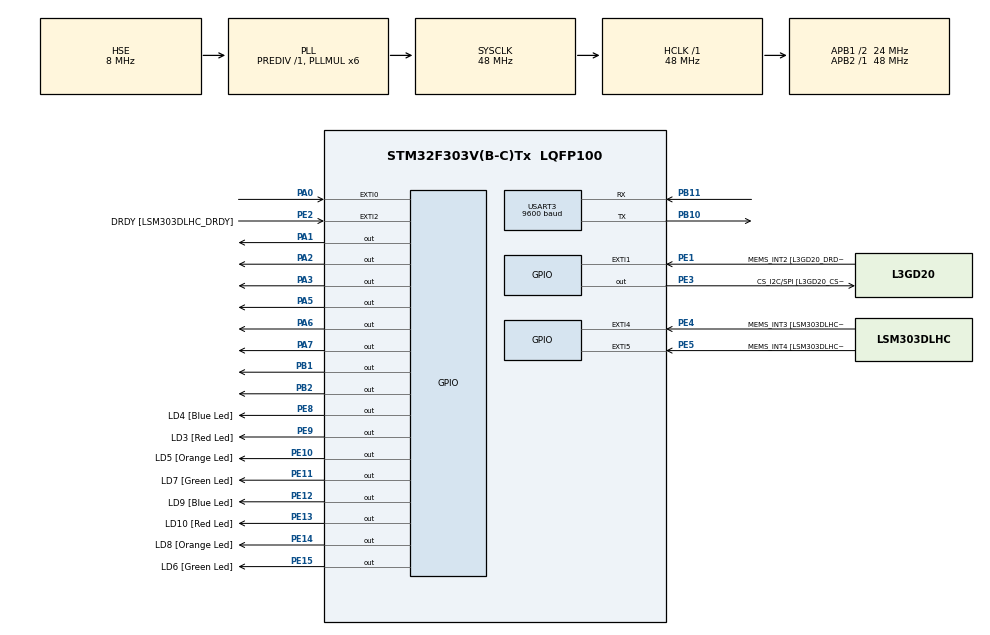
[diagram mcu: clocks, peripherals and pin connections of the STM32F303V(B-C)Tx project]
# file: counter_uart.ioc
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Mcu.Family=STM32F3
Mcu.Name=STM32F303V(B-C)Tx
Mcu.Package=LQFP100
NVIC.EXTI0_IRQn=true\:0\:0\:false\:false\:true\:true\:true
NVIC.PriorityGroup=NVIC_PRIORITYGROUP_1
NVIC.TIM3_IRQn=true\:0\:0\:false\:false\:true\:true\:true
NVIC.TIM4_IRQn=true\:1\:1\:true\:false\:true\:true\:true
PA0.GPIO_ModeDefaultEXTI=GPIO_MODE_IT_RISING_FALLING
PA0.Signal=GPXTI0
PA1.Signal=GPIO_Output
PA11.GPIO_Label=DM
PA11.Signal=USB_DM
PA12.GPIO_Label=DP
PA12.Signal=USB_DP
PA13.GPIO_Label=SWDIO
PA13.Mode=Serial_Wire
PA13.Signal=SYS_JTMS-SWDIO
PA14.GPIO_Label=SWCLK
PA14.Mode=Serial_Wire
PA14.Signal=SYS_JTCK-SWCLK
PA2.Signal=GPIO_Output
PA3.Signal=GPIO_Output
PA5.Signal=GPIO_Output
PA6.Signal=GPIO_Output
PA7.Signal=GPIO_Output
PB1.Signal=GPIO_Output
PB10.Mode=Asynchronous
PB10.Signal=USART3_TX
PB11.Mode=Asynchronous
PB11.Signal=USART3_RX
PB2.Signal=GPIO_Output
PB3.GPIO_Label=SWO
PB3.Signal=SYS_JTDO-TRACESWO
PB6.GPIO_Label=I2C1_SCL [LSM303DLHC_SCL]
PB6.GPIO_Pu=GPIO_PULLUP
PB6.Signal=I2C1_SCL
PB7.GPIO_Label=I2C1_SDA [LSM303DLHC_SDA]
PB7.GPIO_Pu=GPIO_PULLUP
PB7.Signal=I2C1_SDA
PC14-OSC32_IN.GPIO_Label=OSC32_IN
PC14-OSC32_IN.Signal=RCC_OSC32_IN
PC15-OSC32_OUT.GPIO_Label=OSC32_OUT
PC15-OSC32_OUT.Signal=RCC_OSC32_OUT
PE1.GPIO_Label=MEMS_INT2 [L3GD20_DRDY/INT2]
PE1.GPIO_ModeDefaultEXTI=GPIO_MODE_EVT_RISING
PE1.Signal=GPXTI1
PE10.GPIO_Label=LD5 [Orange Led]
PE10.Signal=GPIO_Output
PE11.GPIO_Label=LD7 [Green Led]
PE11.Signal=GPIO_Output
PE12.GPIO_Label=LD9 [Blue Led]
PE12.Signal=GPIO_Output
PE13.GPIO_Label=LD10 [Red Led]
PE13.Signal=GPIO_Output
PE14.GPIO_Label=LD8 [Orange Led]
PE14.Signal=GPIO_Output
PE15.GPIO_Label=LD6 [Green Led]
PE15.Signal=GPIO_Output
PE2.GPIO_Label=DRDY [LSM303DLHC_DRDY]
PE2.GPIO_ModeDefaultEXTI=GPIO_MODE_EVT_RISING
PE2.Signal=GPXTI2
PE3.GPIO_Label=CS_I2C/SPI [L3GD20_CS_I2C/SPI]
PE3.Signal=GPIO_Output
PE4.GPIO_Label=MEMS_INT3 [LSM303DLHC_INT1]
PE4.GPIO_ModeDefaultEXTI=GPIO_MODE_EVT_RISING
PE4.Signal=GPXTI4
PE5.GPIO_Label=MEMS_INT4 [LSM303DLHC_INT2]
PE5.GPIO_ModeDefaultEXTI=GPIO_MODE_EVT_RISING
PE5.Signal=GPXTI5
PE8.GPIO_Label=LD4 [Blue Led]
PE8.Signal=GPIO_Output
PE9.GPIO_Label=LD3 [Red Led]
PE9.Signal=GPIO_Output
PF0-OSC_IN.GPIO_Label=OSC_IN
PF0-OSC_IN.Mode=HSE-External-Clock-Source
PF0-OSC_IN.Signal=RCC_OSC_IN
PF1-OSC_OUT.GPIO_Label=OSC_OUT
PF1-OSC_OUT.Signal=RCC_OSC_OUT
ProjectManager.HeapSize=0x200
ProjectManager.StackSize=0x400
ProjectManager.TargetToolchain=STM32CubeIDE
RCC.AHBFreq_Value=48000000
RCC.APB1CLKDivider=RCC_HCLK_DIV2
RCC.APB1Freq_Value=24000000
RCC.APB1TimFreq_Value=48000000
RCC.APB2Freq_Value=48000000
RCC.APB2TimFreq_Value=48000000
RCC.CortexFreq_Value=48000000
RCC.HCLKFreq_Value=48000000
RCC.HSE_VALUE=8000000
RCC.HSI_VALUE=8000000
RCC.LSE_VALUE=32768
RCC.PLLMUL=RCC_PLL_MUL6
RCC.PLLSourceVirtual=RCC_PLLSOURCE_HSE
RCC.SYSCLKFreq_VALUE=48000000
RCC.SYSCLKSourceVirtual=RCC_SYSCLKSOURCE_PLLCLK
RCC.USBFreq_Value=48000000
TIM3.Period=30000
TIM3.Prescaler=3
TIM4.Period=10000
TIM4.Prescaler=479
USART3.BaudRate=9600
USART3.VirtualMode-Asynchronous=VM_ASYNC
VP_TIM3_VS_ClockSourceINT.Mode=Internal
VP_TIM4_VS_ClockSourceINT.Mode=Internal
board=STM32F3DISCOVERY

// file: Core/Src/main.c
/* USER CODE BEGIN Header */
/**
  ******************************************************************************
  * @file           : main.c
  * @brief          : Main program body
  ******************************************************************************
  * @attention
  *
  * <h2><center>&copy; Copyright (c) 2021 STMicroelectronics.
  * All rights reserved.</center></h2>
  *
  * This software component is licensed by ST under BSD 3-Clause license,
  * the "License"; You may not use this file except in compliance with the
  * License. You may obtain a copy of the License at:
  *                        opensource.org/licenses/BSD-3-Clause
  *
  ******************************************************************************
  */
/* USER CODE END Header */
#include "main.h"

TIM_HandleTypeDef htim3;
TIM_HandleTypeDef htim4;

UART_HandleTypeDef huart3;

void SystemClock_Config(void);
static void MX_GPIO_Init(void);
static void MX_TIM3_Init(void);
static void MX_TIM4_Init(void);
static void MX_USART3_UART_Init(void);

int main(void)
{

  /* MCU Configuration--------------------------------------------------------*/

  /* Reset of all peripherals, Initializes the Flash interface and the Systick. */
  HAL_Init();

  /* Configure the system clock */
  SystemClock_Config();

  /* Initialize all configured peripherals */
  MX_GPIO_Init();
  MX_TIM3_Init();
  MX_TIM4_Init();
  MX_USART3_UART_Init();
  /* USER CODE BEGIN 2 */
  HAL_TIM_Base_Start_IT(&htim3);
  HAL_TIM_Base_Start_IT(&htim4);

  /* USER CODE END 2 */

  /* Infinite loop */
  while (1)
  {

  }
}

void SystemClock_Config(void)
{
  RCC_OscInitTypeDef RCC_OscInitStruct = {0};
  RCC_ClkInitTypeDef RCC_ClkInitStruct = {0};
  RCC_PeriphCLKInitTypeDef PeriphClkInit = {0};

  /** Initializes the RCC Oscillators according to the specified parameters
  * in the RCC_OscInitTypeDef structure.
  */
  RCC_OscInitStruct.OscillatorType = RCC_OSCILLATORTYPE_HSE;
  RCC_OscInitStruct.HSEState = RCC_HSE_BYPASS;
  RCC_OscInitStruct.HSEPredivValue = RCC_HSE_PREDIV_DIV1;
  RCC_OscInitStruct.HSIState = RCC_HSI_ON;
  RCC_OscInitStruct.PLL.PLLState = RCC_PLL_ON;
  RCC_OscInitStruct.PLL.PLLSource = RCC_PLLSOURCE_HSE;
  RCC_OscInitStruct.PLL.PLLMUL = RCC_PLL_MUL6;
  if (HAL_RCC_OscConfig(&RCC_OscInitStruct) != HAL_OK)
  {
    Error_Handler();
  }
  /** Initializes the CPU, AHB and APB buses clocks
  */
  RCC_ClkInitStruct.ClockType = RCC_CLOCKTYPE_HCLK|RCC_CLOCKTYPE_SYSCLK
                              |RCC_CLOCKTYPE_PCLK1|RCC_CLOCKTYPE_PCLK2;
  RCC_ClkInitStruct.SYSCLKSource = RCC_SYSCLKSOURCE_PLLCLK;
  RCC_ClkInitStruct.AHBCLKDivider = RCC_SYSCLK_DIV1;
  RCC_ClkInitStruct.APB1CLKDivider = RCC_HCLK_DIV2;
  RCC_ClkInitStruct.APB2CLKDivider = RCC_HCLK_DIV1;

  if (HAL_RCC_ClockConfig(&RCC_ClkInitStruct, FLASH_LATENCY_1) != HAL_OK)
  {
    Error_Handler();
  }
  PeriphClkInit.PeriphClockSelection = RCC_PERIPHCLK_USART3;
  PeriphClkInit.Usart3ClockSelection = RCC_USART3CLKSOURCE_PCLK1;
  if (HAL_RCCEx_PeriphCLKConfig(&PeriphClkInit) != HAL_OK)
  {
    Error_Handler();
  }
}

static void MX_TIM3_Init(void)
{

  TIM_ClockConfigTypeDef sClockSourceConfig = {0};
  TIM_MasterConfigTypeDef sMasterConfig = {0};

  htim3.Instance = TIM3;
  htim3.Init.Prescaler = 3;
  htim3.Init.CounterMode = TIM_COUNTERMODE_UP;
  htim3.Init.Period = 30000;
  htim3.Init.ClockDivision = TIM_CLOCKDIVISION_DIV1;
  htim3.Init.AutoReloadPreload = TIM_AUTORELOAD_PRELOAD_DISABLE;
  if (HAL_TIM_Base_Init(&htim3) != HAL_OK)
  {
    Error_Handler();
  }
  sClockSourceConfig.ClockSource = TIM_CLOCKSOURCE_INTERNAL;
  if (HAL_TIM_ConfigClockSource(&htim3, &sClockSourceConfig) != HAL_OK)
  {
    Error_Handler();
  }
  sMasterConfig.MasterOutputTrigger = TIM_TRGO_RESET;
  sMasterConfig.MasterSlaveMode = TIM_MASTERSLAVEMODE_DISABLE;
  if (HAL_TIMEx_MasterConfigSynchronization(&htim3, &sMasterConfig) != HAL_OK)
  {
    Error_Handler();
  }

}

static void MX_TIM4_Init(void)
{

  TIM_ClockConfigTypeDef sClockSourceConfig = {0};
  TIM_MasterConfigTypeDef sMasterConfig = {0};

  htim4.Instance = TIM4;
  htim4.Init.Prescaler = 479;
  htim4.Init.CounterMode = TIM_COUNTERMODE_UP;
  htim4.Init.Period = 10000;
  htim4.Init.ClockDivision = TIM_CLOCKDIVISION_DIV1;
  htim4.Init.AutoReloadPreload = TIM_AUTORELOAD_PRELOAD_DISABLE;
  if (HAL_TIM_Base_Init(&htim4) != HAL_OK)
  {
    Error_Handler();
  }
  sClockSourceConfig.ClockSource = TIM_CLOCKSOURCE_INTERNAL;
  if (HAL_TIM_ConfigClockSource(&htim4, &sClockSourceConfig) != HAL_OK)
  {
    Error_Handler();
  }
  sMasterConfig.MasterOutputTrigger = TIM_TRGO_RESET;
  sMasterConfig.MasterSlaveMode = TIM_MASTERSLAVEMODE_DISABLE;
  if (HAL_TIMEx_MasterConfigSynchronization(&htim4, &sMasterConfig) != HAL_OK)
  {
    Error_Handler();
  }

}

static void MX_USART3_UART_Init(void)
{

  huart3.Instance = USART3;
  huart3.Init.BaudRate = 9600;
  huart3.Init.WordLength = UART_WORDLENGTH_8B;
  huart3.Init.StopBits = UART_STOPBITS_1;
  huart3.Init.Parity = UART_PARITY_NONE;
  huart3.Init.Mode = UART_MODE_TX_RX;
  huart3.Init.HwFlowCtl = UART_HWCONTROL_NONE;
  huart3.Init.OverSampling = UART_OVERSAMPLING_16;
  huart3.Init.OneBitSampling = UART_ONE_BIT_SAMPLE_DISABLE;
  huart3.AdvancedInit.AdvFeatureInit = UART_ADVFEATURE_NO_INIT;
  if (HAL_UART_Init(&huart3) != HAL_OK)
  {
    Error_Handler();
  }

}

static void MX_GPIO_Init(void)
{
  GPIO_InitTypeDef GPIO_InitStruct = {0};

  /* GPIO Ports Clock Enable */
  __HAL_RCC_GPIOE_CLK_ENABLE();
  __HAL_RCC_GPIOC_CLK_ENABLE();
  __HAL_RCC_GPIOF_CLK_ENABLE();
  __HAL_RCC_GPIOA_CLK_ENABLE();
  __HAL_RCC_GPIOB_CLK_ENABLE();

  /*Configure GPIO pin Output Level */
  HAL_GPIO_WritePin(GPIOE, CS_I2C_SPI_Pin|LD4_Pin|LD3_Pin|LD5_Pin
                          |LD7_Pin|LD9_Pin|LD10_Pin|LD8_Pin
                          |LD6_Pin, GPIO_PIN_RESET);

  /*Configure GPIO pin Output Level */
  HAL_GPIO_WritePin(GPIOA, GPIO_PIN_1|GPIO_PIN_2|GPIO_PIN_3|GPIO_PIN_5
                          |GPIO_PIN_6|GPIO_PIN_7, GPIO_PIN_RESET);

  /*Configure GPIO pin Output Level */
  HAL_GPIO_WritePin(GPIOB, GPIO_PIN_1|GPIO_PIN_2, GPIO_PIN_RESET);

  /*Configure GPIO pins : DRDY_Pin MEMS_INT3_Pin MEMS_INT4_Pin MEMS_INT2_Pin */
  GPIO_InitStruct.Pin = DRDY_Pin|MEMS_INT3_Pin|MEMS_INT4_Pin|MEMS_INT2_Pin;
  GPIO_InitStruct.Mode = GPIO_MODE_EVT_RISING;
  GPIO_InitStruct.Pull = GPIO_NOPULL;
  HAL_GPIO_Init(GPIOE, &GPIO_InitStruct);

  /*Configure GPIO pins : CS_I2C_SPI_Pin LD4_Pin LD3_Pin LD5_Pin
                           LD7_Pin LD9_Pin LD10_Pin LD8_Pin
                           LD6_Pin */
  GPIO_InitStruct.Pin = CS_I2C_SPI_Pin|LD4_Pin|LD3_Pin|LD5_Pin
                          |LD7_Pin|LD9_Pin|LD10_Pin|LD8_Pin
                          |LD6_Pin;
  GPIO_InitStruct.Mode = GPIO_MODE_OUTPUT_PP;
  GPIO_InitStruct.Pull = GPIO_NOPULL;
  GPIO_InitStruct.Speed = GPIO_SPEED_FREQ_LOW;
  HAL_GPIO_Init(GPIOE, &GPIO_InitStruct);

  /*Configure GPIO pin : PA0 */
  GPIO_InitStruct.Pin = GPIO_PIN_0;
  GPIO_InitStruct.Mode = GPIO_MODE_IT_RISING_FALLING;
  GPIO_InitStruct.Pull = GPIO_NOPULL;
  HAL_GPIO_Init(GPIOA, &GPIO_InitStruct);

  /*Configure GPIO pins : PA1 PA2 PA3 PA5
                           PA6 PA7 */
  GPIO_InitStruct.Pin = GPIO_PIN_1|GPIO_PIN_2|GPIO_PIN_3|GPIO_PIN_5
                          |GPIO_PIN_6|GPIO_PIN_7;
  GPIO_InitStruct.Mode = GPIO_MODE_OUTPUT_PP;
  GPIO_InitStruct.Pull = GPIO_NOPULL;
  GPIO_InitStruct.Speed = GPIO_SPEED_FREQ_LOW;
  HAL_GPIO_Init(GPIOA, &GPIO_InitStruct);

  /*Configure GPIO pins : PB1 PB2 */
  GPIO_InitStruct.Pin = GPIO_PIN_1|GPIO_PIN_2;
  GPIO_InitStruct.Mode = GPIO_MODE_OUTPUT_PP;
  GPIO_InitStruct.Pull = GPIO_NOPULL;
  GPIO_InitStruct.Speed = GPIO_SPEED_FREQ_LOW;
  HAL_GPIO_Init(GPIOB, &GPIO_InitStruct);

  /*Configure GPIO pins : DM_Pin DP_Pin */
  GPIO_InitStruct.Pin = DM_Pin|DP_Pin;
  GPIO_InitStruct.Mode = GPIO_MODE_AF_PP;
  GPIO_InitStruct.Pull = GPIO_NOPULL;
  GPIO_InitStruct.Speed = GPIO_SPEED_FREQ_HIGH;
  GPIO_InitStruct.Alternate = GPIO_AF14_USB;
  HAL_GPIO_Init(GPIOA, &GPIO_InitStruct);

  /*Configure GPIO pins : I2C1_SCL_Pin I2C1_SDA_Pin */
  GPIO_InitStruct.Pin = I2C1_SCL_Pin|I2C1_SDA_Pin;
  GPIO_InitStruct.Mode = GPIO_MODE_AF_OD;
  GPIO_InitStruct.Pull = GPIO_PULLUP;
  GPIO_InitStruct.Speed = GPIO_SPEED_FREQ_HIGH;
  GPIO_InitStruct.Alternate = GPIO_AF4_I2C1;
  HAL_GPIO_Init(GPIOB, &GPIO_InitStruct);

  /* EXTI interrupt init*/
  HAL_NVIC_SetPriority(EXTI0_IRQn, 0, 0);
  HAL_NVIC_EnableIRQ(EXTI0_IRQn);

}

void Error_Handler(void)
{
  __disable_irq();
  while (1)
  {
  }
}

/************************ (C) COPYRIGHT STMicroelectronics *****END OF FILE****/
